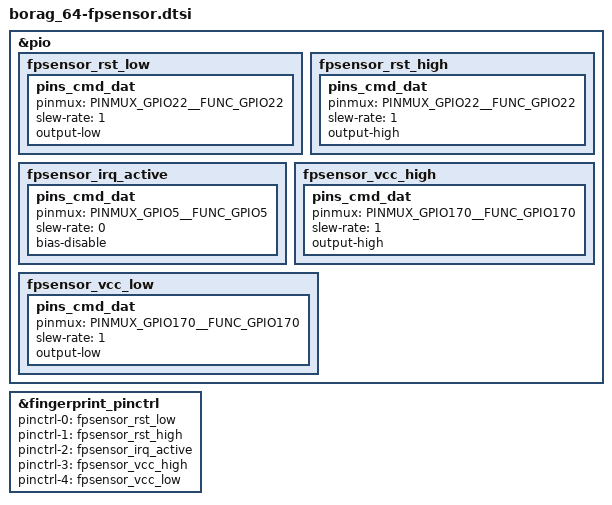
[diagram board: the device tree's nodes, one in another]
/* Copyright (c) 2014, The Linux Foundation. All rights reserved.
*
* This program is free software; you can redistribute it and/or modify
* it under the terms of the GNU General Public License version 2 and
* only version 2 as published by the Free Software Foundation.
*
* This program is distributed in the hope that it will be useful,
* but WITHOUT ANY WARRANTY; without even the implied warranty of
* MERCHANTABILITY or FITNESS FOR A PARTICULAR PURPOSE.  See the
* GNU General Public License for more details.
*/


/*begin, fps, fingerprint config*/
&pio{
    fpsensor_rst_low: fpsensor_rst_low {
        pins_cmd_dat {
            pinmux = <PINMUX_GPIO22__FUNC_GPIO22>;
            slew-rate = <1>;
            output-low;
        };
    };
    fpsensor_rst_high: fpsensor_rst_high {
        pins_cmd_dat {
            pinmux = <PINMUX_GPIO22__FUNC_GPIO22>;
            slew-rate = <1>;
            output-high;
        };
    };
    fpsensor_irq_active: fpsensor_irq_active {
        pins_cmd_dat {
            pinmux = <PINMUX_GPIO5__FUNC_GPIO5>;
            slew-rate = <0>;
            bias-disable;
        };
    };

    fpsensor_vcc_high: fpsensor_vcc_high {
        pins_cmd_dat {
            pinmux = <PINMUX_GPIO170__FUNC_GPIO170>;
            slew-rate = <1>;
            output-high;
        };
    };

    fpsensor_vcc_low: fpsensor_vcc_low {
        pins_cmd_dat {
            pinmux = <PINMUX_GPIO170__FUNC_GPIO170>;
            slew-rate = <1>;
            output-low;
        };
    };
};

&fingerprint_pinctrl{
    pinctrl-names = "fpsensor_rst_low", "fpsensor_rst_high", "fpsensor_irq_active",
            "fpsensor_vcc_high", "fpsensor_vcc_low";
    pinctrl-0 = <&fpsensor_rst_low>;
    pinctrl-1 = <&fpsensor_rst_high>;
    pinctrl-2 = <&fpsensor_irq_active>;
    pinctrl-3 = <&fpsensor_vcc_high>;
    pinctrl-4 = <&fpsensor_vcc_low>;

    status = "okay";
};

/*end, fps, fingerprint config*/
